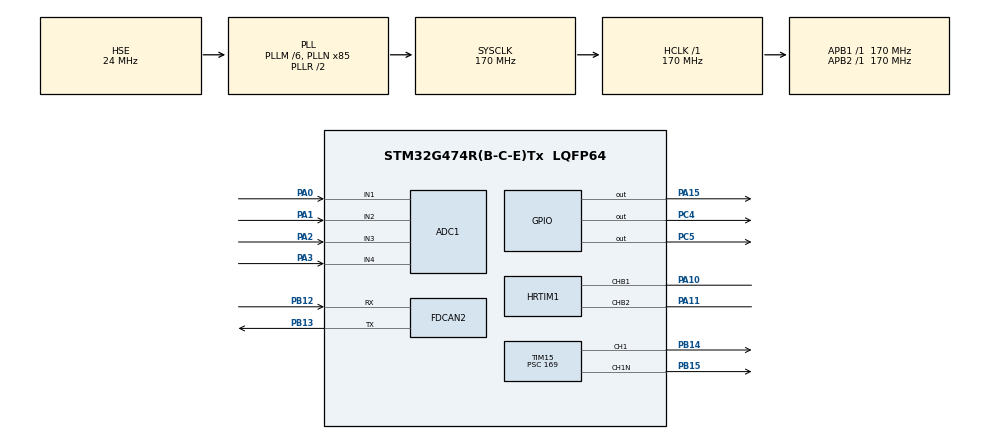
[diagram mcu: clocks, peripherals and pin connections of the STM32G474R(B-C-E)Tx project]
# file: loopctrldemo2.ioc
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ADC1.ContinuousConvMode=DISABLE
ADC1.DMAContinuousRequests=ENABLE
ADC1.EnableInjectedConversion=ENABLE
ADC1.EnableInjectedOversampling=DISABLE
ADC1.EnableRegularConversion=DISABLE
ADC1.ExternalTrigInjecConv=ADC_EXTERNALTRIGINJEC_HRTIM_TRG2
ADC1.ExternalTrigInjecConvEdge=ADC_EXTERNALTRIGINJECCONV_EDGE_RISING
ADC1.InjNumberOfConversion=4
ADC1.InjectedChannel-1\#ChannelInjectedConversion=ADC_CHANNEL_1
ADC1.InjectedChannel-13\#ChannelInjectedConversion=ADC_CHANNEL_2
ADC1.InjectedChannel-14\#ChannelInjectedConversion=ADC_CHANNEL_3
ADC1.InjectedChannel-15\#ChannelInjectedConversion=ADC_CHANNEL_4
ADC1.InjectedOffsetNumber-1\#ChannelInjectedConversion=ADC_OFFSET_NONE
ADC1.InjectedOffsetNumber-13\#ChannelInjectedConversion=ADC_OFFSET_NONE
ADC1.InjectedOffsetNumber-14\#ChannelInjectedConversion=ADC_OFFSET_NONE
ADC1.InjectedOffsetNumber-15\#ChannelInjectedConversion=ADC_OFFSET_NONE
ADC1.InjectedRank-1\#ChannelInjectedConversion=1
ADC1.InjectedRank-13\#ChannelInjectedConversion=2
ADC1.InjectedRank-14\#ChannelInjectedConversion=3
ADC1.InjectedRank-15\#ChannelInjectedConversion=4
ADC1.InjectedSamplingTime-1\#ChannelInjectedConversion=ADC_SAMPLETIME_2CYCLES_5
ADC1.InjectedSamplingTime-13\#ChannelInjectedConversion=ADC_SAMPLETIME_2CYCLES_5
ADC1.InjectedSamplingTime-14\#ChannelInjectedConversion=ADC_SAMPLETIME_2CYCLES_5
ADC1.InjectedSamplingTime-15\#ChannelInjectedConversion=ADC_SAMPLETIME_2CYCLES_5
ADC1.master=1
Dma.ADC1.0.Direction=DMA_PERIPH_TO_MEMORY
Dma.ADC1.0.EventEnable=DISABLE
Dma.ADC1.0.Instance=DMA1_Channel1
Dma.ADC1.0.MemDataAlignment=DMA_MDATAALIGN_HALFWORD
Dma.ADC1.0.MemInc=DMA_MINC_ENABLE
Dma.ADC1.0.Mode=DMA_CIRCULAR
Dma.ADC1.0.PeriphDataAlignment=DMA_PDATAALIGN_HALFWORD
Dma.ADC1.0.PeriphInc=DMA_PINC_DISABLE
Dma.ADC1.0.Polarity=HAL_DMAMUX_REQ_GEN_RISING
Dma.ADC1.0.Priority=DMA_PRIORITY_LOW
Dma.ADC1.0.RequestNumber=1
Dma.ADC1.0.SignalID=NONE
Dma.ADC1.0.SyncEnable=DISABLE
Dma.ADC1.0.SyncPolarity=HAL_DMAMUX_SYNC_NO_EVENT
Dma.ADC1.0.SyncRequestNumber=1
Dma.ADC1.0.SyncSignalID=NONE
Dma.Request0=ADC1
FDCAN2.CalculateBaudRateNominal=1000000
FDCAN2.CalculateTimeBitNominal=1000
FDCAN2.CalculateTimeQuantumNominal=100.0
FDCAN2.DataTimeSeg2=16
FDCAN2.NominalPrescaler=17
FDCAN2.NominalTimeSeg1=5
FDCAN2.NominalTimeSeg2=4
HRTIM1.ADCTrigger2_Source1=HRTIM_ADCTRIGGEREVENT24_TIMERB_CMP2
HRTIM1.ADCTrigger_Id2=HRTIM_ADCTRIGGER_2
HRTIM1.ADCTrigger_Id4=__NULL
HRTIM1.ADCTrigger_Id5=__NULL
HRTIM1.CompareUnit1-MasterTimer=HRTIM_COMPAREUNIT_1
HRTIM1.CompareUnit1-Output_TB1TB2=HRTIM_COMPAREUNIT_1
HRTIM1.CompareUnit2-Output_TB1TB2=HRTIM_COMPAREUNIT_2
HRTIM1.CompareUnit3-Output_TB1TB2=__NULL
HRTIM1.CompareValue1-MasterTimer=0
HRTIM1.CompareValue1-Output_TB1TB2=0
HRTIM1.CompareValue2-Output_TB1TB2=5000
HRTIM1.Configuration_TB=Waveform
HRTIM1.DeadTimeInsertion-Output_TB1TB2=HRTIM_TIMDEADTIMEINSERTION_ENABLED
HRTIM1.FallingValue-Output_TB1TB2=80
HRTIM1.InterruptRequests1-Output_TB1TB2=HRTIM_TIM_IT_CMP2
HRTIM1.NumberADCTriggerSource2=1
HRTIM1.NumberInterruptRequests-Output_TB1TB2=1
HRTIM1.NumberResetSource1-Output_TB1TB2=1
HRTIM1.NumberResetTrigger-Output_TB1TB2=1
HRTIM1.NumberSetSource1-Output_TB1TB2=1
HRTIM1.NumberUpdateTrigger-Output_TB1TB2=0
HRTIM1.ORingUpdateSource_ADCTrigger2=HRTIM_ADCTRIGGERUPDATE_TIMER_B
HRTIM1.Periode_MASTER=21760
HRTIM1.Periode_TB=21760
HRTIM1.Polarity1-Output_TB1TB2=HRTIM_OUTPUTPOLARITY_HIGH
HRTIM1.Polarity2-Output_TB1TB2=HRTIM_OUTPUTPOLARITY_HIGH
HRTIM1.PreloadEnable-MasterTimer=HRTIM_PRELOAD_ENABLED
HRTIM1.PreloadEnable-Output_TB1TB2=HRTIM_PRELOAD_ENABLED
HRTIM1.RepetitionUpdate-Output_TB1TB2=HRTIM_UPDATEONREPETITION_ENABLED
HRTIM1.ResetOutput1_Source1-Output_TB1TB2=HRTIM_OUTPUTRESET_TIMCMP1
HRTIM1.ResetTrigger1-Output_TB1TB2=HRTIM_TIMRESETTRIGGER_MASTER_PER
HRTIM1.ResetUpdate-Output_TB1TB2=HRTIM_TIMUPDATEONRESET_ENABLED
HRTIM1.RisingValue-Output_TB1TB2=80
HRTIM1.SetOutput1_Source1-Output_TB1TB2=HRTIM_OUTPUTSET_TIMPER
HRTIM1.UpDownMode-Output_TB1TB2=HRTIM_TIMERUPDOWNMODE_UP
Mcu.Family=STM32G4
Mcu.Name=STM32G474R(B-C-E)Tx
Mcu.Package=LQFP64
NVIC.ADC1_2_IRQn=true\:0\:0\:true\:false\:true\:true\:true\:true
NVIC.FDCAN2_IT0_IRQn=true\:1\:0\:true\:false\:true\:true\:true\:true
NVIC.FDCAN2_IT1_IRQn=true\:1\:0\:true\:false\:true\:true\:true\:true
NVIC.HRTIM1_TIMB_IRQn=true\:2\:0\:true\:false\:true\:true\:true\:true
NVIC.PriorityGroup=NVIC_PRIORITYGROUP_4
NVIC.TIM1_BRK_TIM15_IRQn=true\:1\:0\:true\:false\:true\:true\:true\:true
NVIC.TIM1_CC_IRQn=true\:1\:0\:true\:false\:true\:true\:true\:true
NVIC.TIM1_TRG_COM_TIM17_IRQn=true\:1\:0\:true\:false\:true\:true\:true\:true
NVIC.TIM1_UP_TIM16_IRQn=true\:1\:0\:true\:false\:true\:true\:true\:true
NVIC.TIM6_DAC_IRQn=true\:1\:0\:true\:false\:true\:true\:true\:true
PA0.Mode=IN1-Single-Ended
PA0.Signal=ADC1_IN1
PA1.Mode=IN2-Single-Ended
PA1.Signal=ADC1_IN2
PA10.Mode=Output_TB1TB2
PA10.Signal=HRTIM1_CHB1
PA11.Mode=Output_TB1TB2
PA11.Signal=HRTIM1_CHB2
PA13.Mode=Serial_Wire
PA13.Signal=SYS_JTMS-SWDIO
PA14.Mode=Serial_Wire
PA14.Signal=SYS_JTCK-SWCLK
PA15.Signal=GPIO_Output
PA2.Mode=IN3-Single-Ended
PA2.Signal=ADC1_IN3
PA3.Mode=IN4-Single-Ended
PA3.Signal=ADC1_IN4
PB12.Mode=FDCAN_Activate
PB12.Signal=FDCAN2_RX
PB13.Mode=FDCAN_Activate
PB13.Signal=FDCAN2_TX
PB14.Signal=S_TIM15_CH1
PB15.Mode=PWM Generation1 CH1 CH1N
PB15.Signal=TIM15_CH1N
PC4.Signal=GPIO_Output
PC5.Signal=GPIO_Output
PF0-OSC_IN.Mode=HSE-External-Oscillator
PF0-OSC_IN.Signal=RCC_OSC_IN
PF1-OSC_OUT.Mode=HSE-External-Oscillator
PF1-OSC_OUT.Signal=RCC_OSC_OUT
ProjectManager.HeapSize=0x400
ProjectManager.StackSize=0x800
ProjectManager.TargetToolchain=MDK-ARM V5.32
RCC.ADC12Freq_Value=170000000
RCC.ADC345Freq_Value=170000000
RCC.AHBFreq_Value=170000000
RCC.APB1Freq_Value=170000000
RCC.APB1TimFreq_Value=170000000
RCC.APB2Freq_Value=170000000
RCC.APB2TimFreq_Value=170000000
RCC.CortexFreq_Value=170000000
RCC.EXTERNAL_CLOCK_VALUE=12288000
RCC.HCLKFreq_Value=170000000
RCC.HSE_VALUE=24000000
RCC.HSI48_VALUE=48000000
RCC.HSI_VALUE=16000000
RCC.LSE_VALUE=32768
RCC.PLLM=RCC_PLLM_DIV6
RCC.PLLN=85
RCC.PLLSourceVirtual=RCC_PLLSOURCE_HSE
RCC.SYSCLKFreq_VALUE=170000000
RCC.SYSCLKSource=RCC_SYSCLKSOURCE_PLLCLK
RCC.USBFreq_Value=170000000
RCC.VCOOutputFreq_Value=340000000
SH.S_TIM15_CH1.0=TIM15_CH1,PWM Generation1 CH1 CH1N
TIM1.PeriodNoDither=200-1
TIM1.Prescaler=170-1
TIM15.AutoReloadPreload=TIM_AUTORELOAD_PRELOAD_ENABLE
TIM15.AutomaticOutput=TIM_AUTOMATICOUTPUT_ENABLE
TIM15.Channel-PWM\ Generation1\ CH1\ CH1N=TIM_CHANNEL_1
TIM15.DeadTime=80
TIM15.DeadTimePreload=ENABLE
TIM15.PeriodNoDither=99
TIM15.Prescaler=169
TIM6.PeriodNoDither=1000-1
TIM6.Prescaler=170-1
VP_ADC1_Vref_Input.Mode=IN-Vrefint
VP_HRTIM1_VS_hrtimMasterTimerNoOutput.Mode=MasterTimer
VP_SYS_VS_DBSignals.Mode=DisableDeadBatterySignals
VP_SYS_V_VREFBUF.Mode=ExternalMode
VP_TIM1_VS_ClockSourceINT.Mode=Internal
VP_TIM6_VS_ClockSourceINT.Mode=Enable_Timer
board=custom

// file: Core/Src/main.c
/* USER CODE BEGIN Header */
/**
  ******************************************************************************
  * @file           : main.c
  * @brief          : Main program body
  ******************************************************************************
  * @attention
  *
  * Copyright (c) 2025 STMicroelectronics.
  * All rights reserved.
  *
  * This software is licensed under terms that can be found in the LICENSE file
  * in the root directory of this software component.
  * If no LICENSE file comes with this software, it is provided AS-IS.
  *
  ******************************************************************************
  */
/* USER CODE END Header */
#include "main.h"
#include "adc.h"
#include "dma.h"
#include "fdcan.h"
#include "hrtim.h"
#include "tim.h"
#include "gpio.h"

/* USER CODE BEGIN Includes */
#include "DCDC.h"
/* USER CODE END Includes */

void SystemClock_Config(void);

int main(void)
{

  /* MCU Configuration--------------------------------------------------------*/

  /* Reset of all peripherals, Initializes the Flash interface and the Systick. */
  HAL_Init();

  /* Configure the system clock */
  SystemClock_Config();

  /* Initialize all configured peripherals */
  MX_GPIO_Init();
  MX_DMA_Init();
  MX_ADC1_Init();
  MX_FDCAN2_Init();
  MX_HRTIM1_Init();
  MX_TIM1_Init();
  MX_TIM15_Init();
  MX_TIM6_Init();
  /* USER CODE BEGIN 2 */
	Cap_Init();

  /* USER CODE END 2 */

  /* Infinite loop */
  while (1)
  {

  }
}

void SystemClock_Config(void)
{
  RCC_OscInitTypeDef RCC_OscInitStruct = {0};
  RCC_ClkInitTypeDef RCC_ClkInitStruct = {0};

  /** Configure the main internal regulator output voltage
  */
  HAL_PWREx_ControlVoltageScaling(PWR_REGULATOR_VOLTAGE_SCALE1_BOOST);

  /** Initializes the RCC Oscillators according to the specified parameters
  * in the RCC_OscInitTypeDef structure.
  */
  RCC_OscInitStruct.OscillatorType = RCC_OSCILLATORTYPE_HSE;
  RCC_OscInitStruct.HSEState = RCC_HSE_ON;
  RCC_OscInitStruct.PLL.PLLState = RCC_PLL_ON;
  RCC_OscInitStruct.PLL.PLLSource = RCC_PLLSOURCE_HSE;
  RCC_OscInitStruct.PLL.PLLM = RCC_PLLM_DIV6;
  RCC_OscInitStruct.PLL.PLLN = 85;
  RCC_OscInitStruct.PLL.PLLP = RCC_PLLP_DIV2;
  RCC_OscInitStruct.PLL.PLLQ = RCC_PLLQ_DIV2;
  RCC_OscInitStruct.PLL.PLLR = RCC_PLLR_DIV2;
  if (HAL_RCC_OscConfig(&RCC_OscInitStruct) != HAL_OK)
  {
    Error_Handler();
  }

  /** Initializes the CPU, AHB and APB buses clocks
  */
  RCC_ClkInitStruct.ClockType = RCC_CLOCKTYPE_HCLK|RCC_CLOCKTYPE_SYSCLK
                              |RCC_CLOCKTYPE_PCLK1|RCC_CLOCKTYPE_PCLK2;
  RCC_ClkInitStruct.SYSCLKSource = RCC_SYSCLKSOURCE_PLLCLK;
  RCC_ClkInitStruct.AHBCLKDivider = RCC_SYSCLK_DIV1;
  RCC_ClkInitStruct.APB1CLKDivider = RCC_HCLK_DIV1;
  RCC_ClkInitStruct.APB2CLKDivider = RCC_HCLK_DIV1;

  if (HAL_RCC_ClockConfig(&RCC_ClkInitStruct, FLASH_LATENCY_4) != HAL_OK)
  {
    Error_Handler();
  }
}

void Error_Handler(void)
{
  __disable_irq();
  while (1)
  {
  }
}
